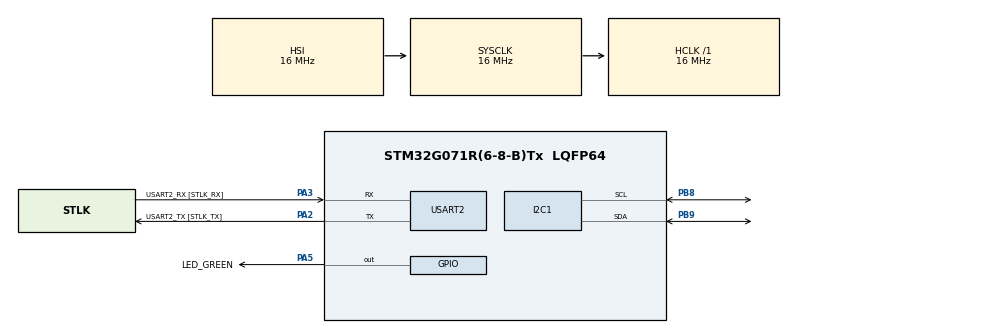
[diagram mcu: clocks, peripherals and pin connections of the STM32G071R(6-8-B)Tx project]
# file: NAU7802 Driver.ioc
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Mcu.Family=STM32G0
Mcu.Name=STM32G071R(6-8-B)Tx
Mcu.Package=LQFP64
PA13.GPIO_Label=TMS
PA13.Mode=Serial_Wire
PA13.Signal=SYS_SWDIO
PA14-BOOT0.GPIO_Label=TCK
PA14-BOOT0.Mode=Serial_Wire
PA14-BOOT0.Signal=SYS_SWCLK
PA2.GPIO_Label=USART2_TX [STLK_TX]
PA2.GPIO_PuPd=GPIO_PULLUP
PA2.Mode=Asynchronous
PA2.Signal=USART2_TX
PA3.GPIO_Label=USART2_RX [STLK_RX]
PA3.GPIO_PuPd=GPIO_PULLUP
PA3.Mode=Asynchronous
PA3.Signal=USART2_RX
PA5.GPIO_Label=LED_GREEN
PA5.GPIO_Speed=GPIO_SPEED_FREQ_HIGH
PA5.Signal=GPIO_Output
PB8.Mode=I2C
PB8.Signal=I2C1_SCL
PB9.Mode=I2C
PB9.Signal=I2C1_SDA
PC13.Mode=SYS_WakeUp1
PC13.Signal=SYS_WKUP2
PC14-OSC32_IN\ (PC14).Mode=LSE-External-Oscillator
PC14-OSC32_IN\ (PC14).Signal=RCC_OSC32_IN
PC15-OSC32_OUT\ (PC15).Mode=LSE-External-Oscillator
PC15-OSC32_OUT\ (PC15).Signal=RCC_OSC32_OUT
PF0-OSC_IN\ (PF0).GPIO_Label=MCO
PF0-OSC_IN\ (PF0).Mode=HSE-External-Clock-Source
PF0-OSC_IN\ (PF0).Signal=RCC_OSC_IN
ProjectManager.HeapSize=0x200
ProjectManager.StackSize=0x400
ProjectManager.TargetToolchain=Makefile
RCC.AHBFreq_Value=16000000
RCC.CortexFreq_Value=16000000
RCC.EXTERNAL_CLOCK_VALUE=12288000
RCC.HCLKFreq_Value=16000000
RCC.HSE_VALUE=8000000
RCC.HSI_VALUE=16000000
RCC.SYSCLKFreq_VALUE=16000000
RCC.VCOOutputFreq_Value=128000000
USART2.VirtualMode-Asynchronous=VM_ASYNC
VP_SYS_VS_DBSignals.Mode=DisableDeadBatterySignals
board=NUCLEO-G071RB

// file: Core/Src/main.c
/* USER CODE BEGIN Header */
/**
 ******************************************************************************
 * @file           : main.c
 * @brief          : Main program body
 ******************************************************************************
 * @attention
 *
 * <h2><center>&copy; Copyright (c) 2021 STMicroelectronics.
 * All rights reserved.</center></h2>
 *
 * This software component is licensed by ST under BSD 3-Clause license,
 * the "License"; You may not use this file except in compliance with the
 * License. You may obtain a copy of the License at:
 *                        opensource.org/licenses/BSD-3-Clause
 *
 ******************************************************************************
 */
/* USER CODE END Header */
#include "main.h"
#include "gpio.h"
#include "i2c.h"
#include "usart.h"

/* USER CODE BEGIN Includes */
#include "nau7802.h"
#include <stdio.h>
#include <string.h>

/* USER CODE END Includes */

void SystemClock_Config(void);
/* USER CODE BEGIN PFP */
void print(char *out_buff);
/* USER CODE END PFP */

int main(void) {
    /* USER CODE BEGIN 1 */
    nau7802_t *adc;

    /* USER CODE END 1 */

    /* MCU Configuration--------------------------------------------------------*/

    /* Reset of all peripherals, Initializes the Flash interface and the Systick. */
    HAL_Init();

    /* Configure the system clock */
    SystemClock_Config();

    /* Initialize all configured peripherals */
    MX_GPIO_Init();
    MX_I2C1_Init();
    MX_USART2_UART_Init();
    /* USER CODE BEGIN 2 */
    adc = nau7802_init(&hi2c1);
    nau7802_powerup_sequence(adc);

    /* USER CODE END 2 */

    /* Infinite loop */
    /* USER CODE BEGIN WHILE */
    uint8_t           pu_reg_state = 0;
    HAL_StatusTypeDef status;
    char              buff[50];
    while (1) {
        /* USER CODE END WHILE */
        status = nau7802_reg_read(adc, NAU7802_REG_PUCTRL, &pu_reg_state);
        nau7802_conversion_read(adc);
        sprintf(buff, "PUCTRL: 0x%x\tStatus: %d\nRaw Reading: %ld\n", pu_reg_state, status, adc->conversion);
        print(buff);

        HAL_Delay(500);
    }
}

void SystemClock_Config(void) {
    RCC_OscInitTypeDef       RCC_OscInitStruct = {0};
    RCC_ClkInitTypeDef       RCC_ClkInitStruct = {0};
    RCC_PeriphCLKInitTypeDef PeriphClkInit = {0};

    /** Configure the main internal regulator output voltage
     */
    HAL_PWREx_ControlVoltageScaling(PWR_REGULATOR_VOLTAGE_SCALE1);
    /** Initializes the RCC Oscillators according to the specified parameters
     * in the RCC_OscInitTypeDef structure.
     */
    RCC_OscInitStruct.OscillatorType = RCC_OSCILLATORTYPE_HSI;
    RCC_OscInitStruct.HSIState = RCC_HSI_ON;
    RCC_OscInitStruct.HSIDiv = RCC_HSI_DIV1;
    RCC_OscInitStruct.HSICalibrationValue = RCC_HSICALIBRATION_DEFAULT;
    RCC_OscInitStruct.PLL.PLLState = RCC_PLL_NONE;
    if (HAL_RCC_OscConfig(&RCC_OscInitStruct) != HAL_OK) {
        Error_Handler();
    }
    /** Initializes the CPU, AHB and APB buses clocks
     */
    RCC_ClkInitStruct.ClockType = RCC_CLOCKTYPE_HCLK | RCC_CLOCKTYPE_SYSCLK | RCC_CLOCKTYPE_PCLK1;
    RCC_ClkInitStruct.SYSCLKSource = RCC_SYSCLKSOURCE_HSI;
    RCC_ClkInitStruct.AHBCLKDivider = RCC_SYSCLK_DIV1;
    RCC_ClkInitStruct.APB1CLKDivider = RCC_HCLK_DIV1;

    if (HAL_RCC_ClockConfig(&RCC_ClkInitStruct, FLASH_LATENCY_0) != HAL_OK) {
        Error_Handler();
    }
    /** Initializes the peripherals clocks
     */
    PeriphClkInit.PeriphClockSelection = RCC_PERIPHCLK_USART2 | RCC_PERIPHCLK_I2C1;
    PeriphClkInit.Usart2ClockSelection = RCC_USART2CLKSOURCE_PCLK1;
    PeriphClkInit.I2c1ClockSelection = RCC_I2C1CLKSOURCE_PCLK1;
    if (HAL_RCCEx_PeriphCLKConfig(&PeriphClkInit) != HAL_OK) {
        Error_Handler();
    }
}

/* USER CODE BEGIN 4 */
void print(char *out_buff) { HAL_UART_Transmit(&huart2, (uint8_t *)out_buff, strlen(out_buff), 0xFFFF); }
/* USER CODE END 4 */

void Error_Handler(void) {
    __disable_irq();
    while (1) {
    }
}

/************************ (C) COPYRIGHT STMicroelectronics *****END OF FILE****/
